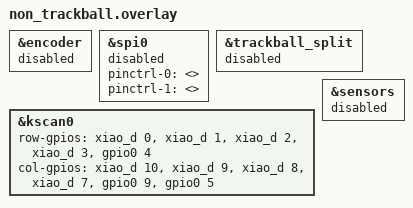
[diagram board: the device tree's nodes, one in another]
&encoder {
    status = "disabled";
};

&spi0 {
    status = "disabled";
    pinctrl-0 = <>;
    pinctrl-1 = <>;
};

&trackball_split {
    status = "disabled";
};

// 物理ピン
&kscan0 {
    row-gpios
        = <&xiao_d 0 (GPIO_ACTIVE_HIGH | GPIO_PULL_DOWN)>   // row0: D0
        , <&xiao_d 1 (GPIO_ACTIVE_HIGH | GPIO_PULL_DOWN)>   // row1: D1
        , <&xiao_d 2 (GPIO_ACTIVE_HIGH | GPIO_PULL_DOWN)>   // row2: D2
        , <&xiao_d 3 (GPIO_ACTIVE_HIGH | GPIO_PULL_DOWN)>   // row3: D3
        , <&gpio0  4 (GPIO_ACTIVE_HIGH | GPIO_PULL_DOWN)>   // row4: D4 (P0.04)
        ; 

    col-gpios
        = <&xiao_d 10 GPIO_ACTIVE_HIGH>                     // col0: D10
        , <&xiao_d 9  GPIO_ACTIVE_HIGH>                     // col1: D9
        , <&xiao_d 8  GPIO_ACTIVE_HIGH>                     // col2: D8
        , <&xiao_d 7  GPIO_ACTIVE_HIGH>                     // col3: D7
        , <&gpio0  9  GPIO_ACTIVE_HIGH>                     // col4: GPIO9(NFC1)
        , <&gpio0  5  GPIO_ACTIVE_HIGH>                     // col5: D5 (P0.05)
        ; 
};

&sensors {
    status = "disabled";
};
